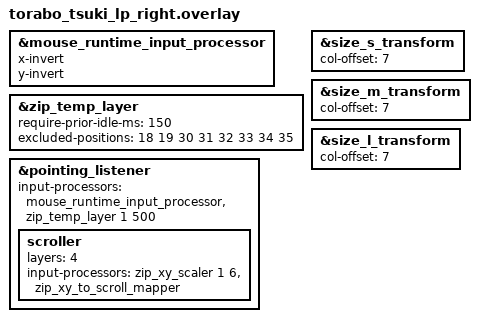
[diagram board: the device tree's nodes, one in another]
#include "torabo_tsuki_lp.dtsi"
#include <input/processors.dtsi>
#include <input/processors/runtime-input-processor.dtsi>
#include <dt-bindings/zmk/input_transform.h>

&mouse_runtime_input_processor {
    // DYA Studio から速度(scale)/回転(rotation)/軸スナップ等を再ビルド無しで実機調整できる。
    // 既定値は従来の zip_xy_transform(X/Y反転) 相当。調整値はStudioのみ保持されソースには戻らない。
    x-invert;
    y-invert;
};

&zip_temp_layer {
    // タイピング直後150msはポインタ移動でマウスレイヤーを起動しない（誤爆防止）
    require-prior-idle-ms = <150>;
    // マウス操作キーだけは押下してもオートマウスレイヤーを維持する。
    excluded-positions = <18 19 30 31 32 33 34 35>;
};

&pointing_listener {
    // ポインタ移動を runtime processor で処理（DYA Studioで調整可）→ layer_1自動有効化・500ms無操作で解除
    input-processors =
        <&mouse_runtime_input_processor>,
        <&zip_temp_layer 1 500>;

    // layer_4 が有効な間だけ、移動を1/6に減速してスクロールへ変換（ホールド式スクロール）
    scroller {
        layers = <4>;
        input-processors = <&zip_xy_scaler 1 6>, <&zip_xy_to_scroll_mapper>;
    };
};

&size_s_transform {
    col-offset = <7>;
};

&size_m_transform {
    col-offset = <7>;
};

&size_l_transform {
    col-offset = <7>;
};
